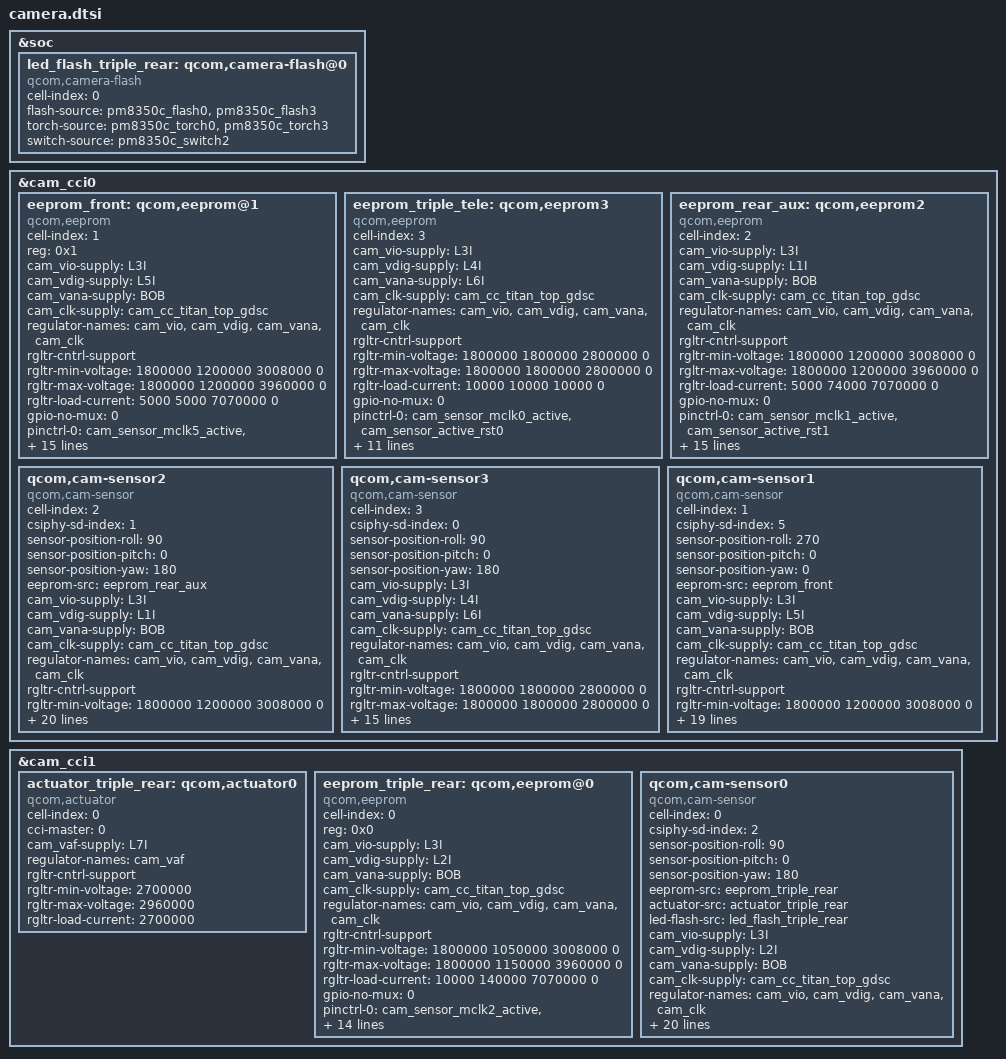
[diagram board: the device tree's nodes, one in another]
&soc {
   led_flash_triple_rear: qcom,camera-flash@0 {
                cell-index = <0>;
                compatible = "qcom,camera-flash";
                flash-source = <&pm8350c_flash0 &pm8350c_flash3>;
                torch-source = <&pm8350c_torch0 &pm8350c_torch3>;
                switch-source = <&pm8350c_switch2>;
                status = "ok";
        };
};

&cam_cci0 {
	eeprom_front: qcom,eeprom@1 {
		cell-index = <1>;
		compatible = "qcom,eeprom";
		reg = <0x1>;
		cam_vio-supply = <&L3I>; 
		cam_vdig-supply = <&L5I>;//
		//cam_bob-supply = <&BOB>;
		cam_vana-supply = <&BOB>;
		cam_clk-supply = <&cam_cc_titan_top_gdsc>;
		regulator-names = "cam_vio","cam_vdig","cam_vana","cam_clk";
		rgltr-cntrl-support;
		rgltr-min-voltage = <1800000 1200000 3008000 0>;
		rgltr-max-voltage = <1800000 1200000 3960000 0>;
		rgltr-load-current = <5000 5000 7070000 0>;
		gpio-no-mux = <0>;
		pinctrl-names = "cam_default", "cam_suspend";
		pinctrl-0 = <&cam_sensor_mclk5_active
				 &cam_sensor_active_rst5>;
		pinctrl-1 = <&cam_sensor_mclk5_suspend
				 &cam_sensor_suspend_rst5>;
		gpios = <&tlmm 105 0>, //  mclk  669 105  679 105
			<&tlmm 118 0>,//reset 669  115 679   118
			<&tlmm 99 0>; //van  669 77 679  99
		gpio-reset = <1>;
		gpio-vana = <2>;
		gpio-req-tbl-num = <0 1 2>;
		gpio-req-tbl-flags = <1 0 0>;
		gpio-req-tbl-label = "CAMIF_MCLK5",
					"CAM_RESET5",
					"CAM_VANA5";
		cci-master = <0>;
		cci-device = <0>;
		status = "ok";
		clocks = <&clock_camcc CAM_CC_MCLK5_CLK>;
		clock-names = "cam_clk";
		clock-cntl-level = "nominal";
		clock-rates = <19200000>;
	};

	//2M-EEPROM
	eeprom_triple_tele: qcom,eeprom3 {
		cell-index = <3>;
		compatible = "qcom,eeprom";
		cam_vio-supply = <&L3I>;
		//cam_vana-supply = <&pm8350c_bob>;
		cam_vdig-supply = <&L4I>;
		cam_vana-supply = <&L6I>;
		cam_clk-supply = <&cam_cc_titan_top_gdsc>;
		//cam_bob-supply = <&pm8350c_bob>;
		regulator-names = "cam_vio", "cam_vdig","cam_vana","cam_clk";
		rgltr-cntrl-support;
		rgltr-min-voltage = <1800000 1800000 2800000 0>;
		rgltr-max-voltage = <1800000 1800000 2800000 0>;
		rgltr-load-current = <10000 10000 10000 0>;
		gpio-no-mux = <0>;
		pinctrl-names = "cam_default", "cam_suspend";
		pinctrl-0 = <&cam_sensor_mclk0_active
				&cam_sensor_active_rst0>;
		pinctrl-1 = <&cam_sensor_mclk0_suspend
				&cam_sensor_suspend_rst0>;
		gpios = <&tlmm 100 0>, //MCLK 669 100  679 100
			<&tlmm 25 0>;//reset 669  17  679  25
		gpio-reset = <1>;
		gpio-req-tbl-num = <0 1>;
		gpio-req-tbl-flags = <1 0>;
		gpio-req-tbl-label = "CAMIF_MCLK0",
					"CAM_RESET0";
		cci-master = <0>;
		status = "ok";
		clocks = <&clock_camcc CAM_CC_MCLK0_CLK>;
		clock-names = "cam_clk";
		clock-cntl-level = "nominal";
		clock-rates = <24000000>;
	};
	eeprom_rear_aux: qcom,eeprom2 {
		cell-index = <2>;
		compatible = "qcom,eeprom";
		cam_vio-supply = <&L3I>; //dovdd
		cam_vdig-supply = <&L1I>; //dvdd L1
		cam_vana-supply = <&BOB>;
		cam_clk-supply = <&cam_cc_titan_top_gdsc>;
		regulator-names = "cam_vio","cam_vdig","cam_vana","cam_clk";
		rgltr-cntrl-support;
		rgltr-min-voltage = <1800000 1200000 3008000 0>;
		rgltr-max-voltage = <1800000 1200000 3960000 0>;
		rgltr-load-current = <5000   74000   7070000 0>;
		gpio-no-mux = <0>;
		pinctrl-names = "cam_default", "cam_suspend";
		pinctrl-0 = <&cam_sensor_mclk1_active
					 &cam_sensor_active_rst1>;
		pinctrl-1 = <&cam_sensor_mclk1_suspend
					 &cam_sensor_suspend_rst1>;
		gpios = <&tlmm 101 0>, //mclk   669  101  679  101
			<&tlmm 24 0>,//reset 669 16  679 24
			<&tlmm 106 0>,//CAM_STANDBY1  669  50 679  106
			<&tlmm 107 0>; //avdd 669 47  679  107
		gpio-reset = <1>;
		gpio-standby = <2>;
		gpio-vana = <3>;
		gpio-req-tbl-num = <0 1 2 3>;
		gpio-req-tbl-flags = <1 0 0 0>;
		gpio-req-tbl-label = "CAMIF_MCLK1",
							 "CAM_RESET1",
							 "CAM_STANDBY1",
							 "CAM_VANA1";
		cci-master = <1>;
		cci-device = <1>;
		status = "ok";
		clocks = <&clock_camcc CAM_CC_MCLK1_CLK>;
		clock-names = "cam_clk";
		clock-cntl-level = "turbo";
		clock-rates = <19200000>;
	};

//8Mback
	qcom,cam-sensor2 {
		cell-index = <2>;
		compatible = "qcom,cam-sensor";
		csiphy-sd-index = <1>;
		sensor-position-roll = <90>;
		sensor-position-pitch = <0>;
		sensor-position-yaw = <180>;
		eeprom-src = <&eeprom_rear_aux>;
		cam_vio-supply = <&L3I>; //dovdd
		cam_vdig-supply = <&L1I>; //dvdd L1
		cam_vana-supply = <&BOB>;
		cam_clk-supply = <&cam_cc_titan_top_gdsc>;
		regulator-names = "cam_vio","cam_vdig","cam_vana","cam_clk";
		rgltr-cntrl-support;
		rgltr-min-voltage = <1800000 1200000 3008000 0>;
		rgltr-max-voltage = <1800000 1200000 3960000 0>;
		rgltr-load-current = <5000   74000   7070000 0>;
		gpio-no-mux = <0>;
		pinctrl-names = "cam_default", "cam_suspend";
		pinctrl-0 = <&cam_sensor_mclk1_active
					 &cam_sensor_active_rst1>;
		pinctrl-1 = <&cam_sensor_mclk1_suspend
					 &cam_sensor_suspend_rst1>;
		gpios = <&tlmm 101 0>, //mclk   669  101  679  101
			<&tlmm 24 0>,//reset 669 16  679 24
			<&tlmm 106 0>,//CAM_STANDBY1  669  50 679  106
			<&tlmm 107 0>; //avdd 669 47  679  107
		gpio-reset = <1>;
		gpio-standby = <2>;
		gpio-vana = <3>;
		gpio-req-tbl-num = <0 1 2 3>;
		gpio-req-tbl-flags = <1 0 0 0>;
		gpio-req-tbl-label = "CAMIF_MCLK1",
							 "CAM_RESET1",
							 "CAM_STANDBY1",
							 "CAM_VANA1";
		cci-master = <1>;
		cci-device = <1>;
		status = "ok";
		clocks = <&clock_camcc CAM_CC_MCLK1_CLK>;
		clock-names = "cam_clk";
		clock-cntl-level = "turbo";
		clock-rates = <19200000>;
	};
//2M
	qcom,cam-sensor3 {   
		cell-index = <3>;
		compatible = "qcom,cam-sensor";
		csiphy-sd-index = <0>;
		sensor-position-roll = <90>;
		sensor-position-pitch = <0>;
		sensor-position-yaw = <180>;
		//eeprom-src = <&eeprom_triple_tele>;
		//actuator-src = <&actuator_triple_tele>;
		//led-flash-src = <&led_flash_triple_rear_aux>;
		cam_vio-supply = <&L3I>;
		//cam_vana-supply = <&pm8350c_bob>;
		cam_vdig-supply = <&L4I>;
		cam_vana-supply = <&L6I>;
		cam_clk-supply = <&cam_cc_titan_top_gdsc>;
		//cam_bob-supply = <&pm8350c_bob>;
		regulator-names = "cam_vio", "cam_vdig","cam_vana","cam_clk";
		rgltr-cntrl-support;
		rgltr-min-voltage = <1800000 1800000 2800000 0>;
		rgltr-max-voltage = <1800000 1800000 2800000 0>;
		rgltr-load-current = <10000 10000 10000 0>;
		gpio-no-mux = <0>;
		pinctrl-names = "cam_default", "cam_suspend";
		pinctrl-0 = <&cam_sensor_mclk0_active
				&cam_sensor_active_rst0>;
		pinctrl-1 = <&cam_sensor_mclk0_suspend
				&cam_sensor_suspend_rst0>;
		gpios = <&tlmm 100 0>, //MCLK 669 100  679 100
			<&tlmm 25 0>;//reset 669  17  679  25
		gpio-reset = <1>;
		gpio-req-tbl-num = <0 1>;
		gpio-req-tbl-flags = <1 0>;
		gpio-req-tbl-label = "CAMIF_MCLK0",
					"CAM_RESET0";
		cci-master = <0>;
		status = "ok";
		clocks = <&clock_camcc CAM_CC_MCLK0_CLK>;
		clock-names = "cam_clk";
		clock-cntl-level = "nominal";
		clock-rates = <24000000>;
	};

	qcom,cam-sensor1 {
		cell-index = <1>;
		compatible = "qcom,cam-sensor";
		csiphy-sd-index = <5>;
		sensor-position-roll = <270>;
		sensor-position-pitch = <0>;
		sensor-position-yaw = <0>;
		eeprom-src = <&eeprom_front>;
		cam_vio-supply = <&L3I>; 
		cam_vdig-supply = <&L5I>;//
		//cam_bob-supply = <&BOB>;
		cam_vana-supply = <&BOB>;
		cam_clk-supply = <&cam_cc_titan_top_gdsc>;
		regulator-names = "cam_vio","cam_vdig","cam_vana","cam_clk";
		rgltr-cntrl-support;
		rgltr-min-voltage = <1800000 1200000 3008000 0>;
		rgltr-max-voltage = <1800000 1200000 3960000 0>;
		rgltr-load-current = <5000 5000 7070000 0>;
		gpio-no-mux = <0>;
		pinctrl-names = "cam_default", "cam_suspend";
		pinctrl-0 = <&cam_sensor_mclk5_active
				 &cam_sensor_active_rst5>;
		pinctrl-1 = <&cam_sensor_mclk5_suspend
				 &cam_sensor_suspend_rst5>;
		gpios = <&tlmm 105 0>, //  mclk  669 105  679 105
			<&tlmm 118 0>,//reset 669  115 679   118
			<&tlmm 99 0>; //van  669 77 679  99
		gpio-reset = <1>;
		gpio-vana = <2>;
		gpio-req-tbl-num = <0 1 2>;
		gpio-req-tbl-flags = <1 0 0>;
		gpio-req-tbl-label = "CAMIF_MCLK5",
					"CAM_RESET5",
					"CAM_VANA5";
		cci-master = <0>;
		cci-device = <0>;
		status = "ok";
		clocks = <&clock_camcc CAM_CC_MCLK5_CLK>;
		clock-names = "cam_clk";
		clock-cntl-level = "nominal";
		clock-rates = <19200000>;
	};
};

&cam_cci1 {
	actuator_triple_rear: qcom,actuator0 {
		cell-index = <0>;
		compatible = "qcom,actuator";
		cci-master = <0>;
		cam_vaf-supply = <&L7I>;
		regulator-names = "cam_vaf";
		rgltr-cntrl-support;
		rgltr-min-voltage = <2700000>;
		rgltr-max-voltage = <2960000>;
		rgltr-load-current = <2700000>;
	};

	eeprom_triple_rear: qcom,eeprom@0 {
		cell-index = <0>;
		compatible = "qcom,eeprom";
		reg = <0x0>;
		cam_vio-supply = <&L3I>; //dovdd  compre demo us used I PIMC
		cam_vdig-supply = <&L2I>;//dvdd
		cam_vana-supply = <&BOB>;
		cam_clk-supply = <&cam_cc_titan_top_gdsc>;
		regulator-names = "cam_vio", "cam_vdig", "cam_vana",
			"cam_clk";
		rgltr-cntrl-support;
		rgltr-min-voltage = <1800000 1050000 3008000 0>;
		rgltr-max-voltage = <1800000 1150000 3960000 0>;
		rgltr-load-current = <10000 140000 7070000 0>;
		gpio-no-mux = <0>;
		pinctrl-names = "cam_default", "cam_suspend";
		pinctrl-0 = <&cam_sensor_mclk2_active
				&cam_sensor_active_rst2>;
		pinctrl-1 = <&cam_sensor_mclk2_suspend
				&cam_sensor_suspend_rst2>;
		gpios = <&tlmm 102 0>,	// 669 102  679 102
		    <&tlmm 117 0>,	// 669 106  679 117
			<&tlmm 108 0>;	//669 avdd 93  679 108
		gpio-reset = <1>;
		gpio-vana = <2>;
		gpio-req-tbl-num = <0 1 2>;
		gpio-req-tbl-flags = <1 0 0>;
		gpio-req-tbl-label = "CAMIF_MCLK0",
					"CAM_RESET0",
					"CAM_VANA0"; //avdd
		cci-master = <0>;
		status = "ok";
		clocks = <&clock_camcc CAM_CC_MCLK2_CLK>;
		clock-names = "cam_clk";
		clock-cntl-level = "nominal";
		clock-rates = <19200000>;
	};

	qcom,cam-sensor0 {
		cell-index = <0>;
		compatible = "qcom,cam-sensor";
		csiphy-sd-index = <2>;
		sensor-position-roll = <90>;
		sensor-position-pitch = <0>;
		sensor-position-yaw = <180>;
		eeprom-src = <&eeprom_triple_rear>;
		actuator-src = <&actuator_triple_rear>;
		led-flash-src = <&led_flash_triple_rear>;
		cam_vio-supply = <&L3I>; //dovdd  compre demo us used I PIMC
		cam_vdig-supply = <&L2I>;//dvdd 
		cam_vana-supply = <&BOB>;
		cam_clk-supply = <&cam_cc_titan_top_gdsc>;
		regulator-names = "cam_vio", "cam_vdig", "cam_vana",
			"cam_clk";
		rgltr-cntrl-support;
		rgltr-min-voltage = <1800000 1050000 3008000 0>;
		rgltr-max-voltage = <1800000 1150000 3960000 0>;
		rgltr-load-current = <10000 140000 7070000 0>;
		gpio-no-mux = <0>;
		pinctrl-names = "cam_default", "cam_suspend";
		pinctrl-0 = <&cam_sensor_mclk2_active
				&cam_sensor_active_rst2>;
		pinctrl-1 = <&cam_sensor_mclk2_suspend
				&cam_sensor_suspend_rst2>;
		gpios = <&tlmm 102 0>,	// 669 102  679 102
		    <&tlmm 117 0>,	// 669 106  679 117
			<&tlmm 108 0>;	//669 avdd 93  679 108
		gpio-reset = <1>;
		gpio-vana = <2>;
		gpio-req-tbl-num = <0 1 2>;
		gpio-req-tbl-flags = <1 0 0>;
		gpio-req-tbl-label = "CAMIF_MCLK0",
					"CAM_RESET0",
					"CAM_VANA0"; //avdd
		cci-master = <0>;
		status = "ok";
		clocks = <&clock_camcc CAM_CC_MCLK2_CLK>;
		clock-names = "cam_clk";
		clock-cntl-level = "nominal";
		clock-rates = <19200000>;
	};
};
